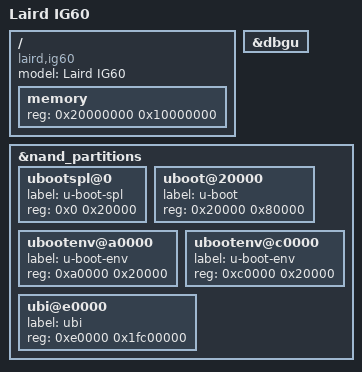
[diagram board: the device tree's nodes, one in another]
/*
 * at91-ig60.dts - Device Tree file for Laird IG60, based on SOM60x2 module
 *
 *  Copyright (C) 2018 Laird,
 *		  2018 Ben Whitten <ben.whitten@lairdconnect.com>
 *		  2018 Boris Krasnovskiy <boris.krasnovskiy@lairdconnect.com>
 *
 * Licensed under GPLv2 or later.
 */

/dts-v1/;

#include "at91-som60_common.dtsi"
#include "at91-ig60.dtsi"

/ {
	model = "Laird IG60";
	compatible = "laird,ig60", "atmel,sama5d36", "atmel,sama5d3", "atmel,sama5";

	memory {
		reg = <0x20000000 0x10000000>;
	};
};

&dbgu {
	status = "okay";
};

&nand_partitions {
	ubootspl@0 {
		label = "u-boot-spl";
		reg = <0x0 0x20000>;
	};

	uboot@20000 {
		label = "u-boot";
		reg = <0x20000 0x80000>;
	};

	ubootenv@a0000 {
		label = "u-boot-env";
		reg = <0xa0000 0x20000>;
	};

	ubootenv@c0000 {
		label = "u-boot-env";
		reg = <0xc0000 0x20000>;
	};

	ubi@e0000 {
		label = "ubi";
		reg = <0xe0000 0x1fc00000>;
	};
};
